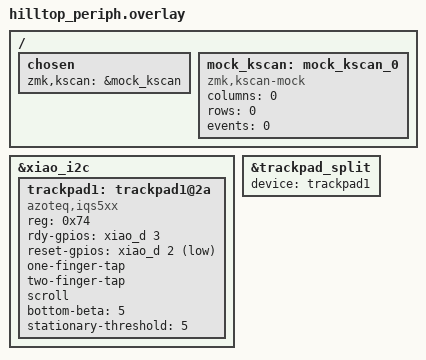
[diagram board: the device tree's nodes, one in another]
#include "hilltop.dtsi"
#include "split_inputs.dtsi"

/ {
    chosen {
        zmk,kscan = &mock_kscan;
    };

    mock_kscan: mock_kscan_0 {
        compatible = "zmk,kscan-mock";
        columns = <0>;
        rows = <0>;
        events = <0>;
    };
};

&xiao_i2c {
    status = "okay";
    
    trackpad1: trackpad1@2a {
        compatible = "azoteq,iqs5xx";
        reg = <0x74>;
        status = "okay";

        rdy-gpios = <&xiao_d 3 (GPIO_ACTIVE_HIGH)>;
        reset-gpios = <&xiao_d 2 (GPIO_ACTIVE_LOW)>;

        one-finger-tap;
        //press-and-hold;
        //press-and-hold-time = <250>;
        two-finger-tap;

        scroll;
        //natural-scroll-y;
        //natural-scroll-x;

        bottom-beta = <5>;  //mount of filtering applied at slow speeds.
            //0: Most filtering, smoother, but laggier.
            //255: Least filtering, least smooth, more responsive.
        stationary-threshold = <5>; //How far a finger must move (in pixels) to not be considered stationary.
            //default 5

        //switch-xy;
    };
};

// Overrides for the input-split child node
&trackpad_split {
    device = <&trackpad1>;
    // Optional
    // input-processors = <&zip_xy_transform (INPUT_TRANSFORM_XY_SWAP | INPUT_TRANSFORM_X_INVERT | INPUT_TRANSFORM_Y_INVERT)>;
};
